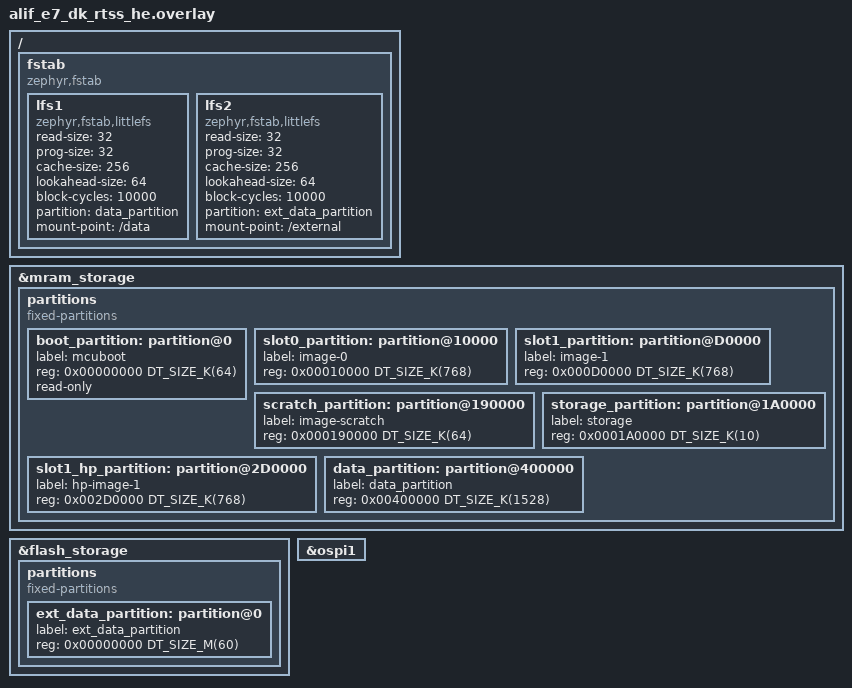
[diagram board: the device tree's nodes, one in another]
// Confidential - Copyright PA.COTTE: All rights reserved

&mram_storage {
  partitions {
    compatible = "fixed-partitions";
    #address-cells = <1>;
    #size-cells = <1>;
    /* MCUBoot */
    boot_partition: partition@0 {
      label = "mcuboot";
      reg = <0x00000000 DT_SIZE_K(64)>;
      read-only;
    };
    /* MCUBoot update slots */
    slot0_partition: partition@10000 {
      label = "image-0";
      reg = <0x00010000 DT_SIZE_K(768)>;
    };
    slot1_partition: partition@D0000 {
      label = "image-1";
      reg = <0x000D0000 DT_SIZE_K(768)>;
    };
    scratch_partition: partition@190000 {
      label = "image-scratch";
      reg = <0x000190000 DT_SIZE_K(64)>;
    };
    storage_partition: partition@1A0000 {
      label = "storage";
      reg = <0x0001A0000 DT_SIZE_K(10)>;
    };
    /* MCUBoot Obelix update slot */
    slot1_hp_partition: partition@2D0000 {
      label = "hp-image-1";
      reg = <0x002D0000 DT_SIZE_K(768)>;
    };
    /* LFS image partitions */
    data_partition: partition@400000 {
      label = "data_partition";
      reg = <0x00400000 DT_SIZE_K(1528)>;// 1.5 MiB (keep last 7 KB free, TOC written from 0x8057E640)
    };
  };
};


&flash_storage {
  partitions {
    compatible = "fixed-partitions";
    #address-cells = <1>;
    #size-cells = <1>;
    /* LFS image partitions */
    ext_data_partition: partition@0 {
      label = "ext_data_partition";
      reg = <0x00000000 DT_SIZE_M(60)>;// full size 64MB
    };
  };
};


/ {
  fstab {
    compatible = "zephyr,fstab";
    lfs1: lfs1 {
      compatible = "zephyr,fstab,littlefs";
      read-size = <32>;
      prog-size = <32>;
      cache-size = <256>;
      lookahead-size = <64>;
      block-cycles = <10000>;// 10k cycles
      partition = <&data_partition>;
      mount-point = "/data";
    };
    lfs2: lfs2 {
      compatible = "zephyr,fstab,littlefs";
      read-size = <32>;
      prog-size = <32>;
      cache-size = <256>;
      lookahead-size = <64>;
      block-cycles = <10000>;// 10k cycles
      partition = <&ext_data_partition>;
      mount-point = "/external";
    };
  };
};


&ospi1 {
  status = "okay";
};
